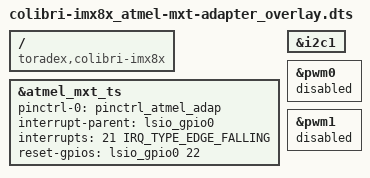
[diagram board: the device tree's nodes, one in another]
// SPDX-License-Identifier: GPL-2.0-or-later OR MIT
/*
 * Copyright 2020-2021 Toradex
 */

// Atmel MXT touchscreen for Capacitive Touch Adapter.
// Supports the 7 inch and 10 inch capacitive touch displays orderable at Toradex.

/dts-v1/;
/plugin/;

#include "dt-bindings/interrupt-controller/irq.h"
#include "dt-bindings/gpio/gpio.h"

/ {
	compatible = "toradex,colibri-imx8x";
};

&atmel_mxt_ts {
	pinctrl-0 = <&pinctrl_atmel_adap>;
	interrupt-parent = <&lsio_gpio0>;
	interrupts = <21 IRQ_TYPE_EDGE_FALLING>;		/* SODIMM 28 */
	reset-gpios = <&lsio_gpio0 22 GPIO_ACTIVE_HIGH>;	/* SODIMM 30 */
	status = "okay";
};

&i2c1 {
	status = "okay";
};

&pwm0 {
	status = "disabled";
};

&pwm1 {
	status = "disabled";
};
